AUTOSAR XML (schema 00052)
standard types defined: boolean, float32, uint16, uint8, boolean_CompuMethod
package /AUTOSAR_Platform/ImplementationDataTypes
  impl type uint8_const: category=VALUE, base-type=uint8, additional-native-type-qualifier=const  # uint8 represents integers with a minimum value of 0 and a maximum value of 255. The order-relation on uint8 is: x < y if y - x is positive. uint8 has a lexical representation consisting of a finite-length sequence of decimal digits (#x30-#x39). For example: 1, 0, 126, +10.
  impl type uint16_const: category=VALUE, base-type=uint16, additional-native-type-qualifier=const  # uint16 represents integers with a minimum value of 0 and a maximum value of 65535. The order-relation on uint16 is: x < y if y - x is positive. uint16 has a lexical representation consisting of a finite-length sequence of decimal digits (#x30-#x39). For example: 1, 0, 1267, +10000.
  impl type float32_const: category=VALUE, base-type=float32, additional-native-type-qualifier=const  # float32 corresponds to the IEEE single-precision 32-bit floating point type [IEEE 754-1985]. The basic value space of float32 consists of the values m * 2^e, where m is an integer whose absolute value is less than 2^24, and e is an integer between -149 and 104, inclusive. In addition to the basic value space described above, the value space of float32 also contains the following special values: positive and negative zero, positive and negative infinity and not-a-number. The order-relation on float32 is: x < y if y - x is positive. Positive zero is greater than negative zero. Not-a-number equals itself and is greater than all float values including positive infinity. float32 values have a lexical representation consisting of a mantissa followed, optionally, by the character "E" or "e", followed by an exponent. The exponent must be an integer. The mantissa must be a decimal number. The representations for exponent and mantissa must follow the lexical rules for integer and decimal. If the "E" or "e" and the following exponent are omitted, an exponent value of 0 is assumed. The special values positive and negative zero, positive and negative infinity and not-a-number have lexical representations 0, -0, INF, -INF and NaN, respectively. For example, -1E4, 1267.43233E12, 12.78e-2, 12 and INF are all legal literals for float32.
package /AUTOSAR_Platform/ImplementationDataTypes/SwAddrMethods
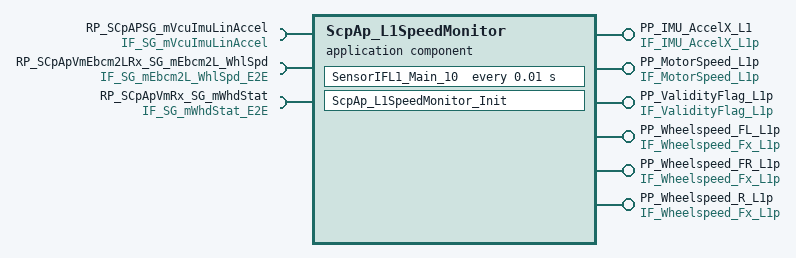
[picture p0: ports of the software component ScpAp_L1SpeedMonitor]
  application sw component type ScpAp_L1SpeedMonitor
    require port RP_SCpAPSG_mVcuImuLinAccel: nonqueued-receiver-com-spec{data-element=SG_mVcuImuLinAccel_VDP, init-value={short-label=DefaultInitValue_SG_mVcuImuLinAccel_IDT, fields=[0, 0, 0, 0, 0]}}, required-interface=IF_SG_mVcuImuLinAccel
    require port RP_SCpApVmEbcm2LRx_SG_mEbcm2L_WhlSpd: nonqueued-receiver-com-spec{data-element=SG_mEbcm2L_WhlSpd, init-value={short-label=ComSpec340e8554_2c4f562b67451db0, fields=[MsgCntr_mEbcm2L_WhlSpd:0, MsgCrc_mEbcm2L_WhlSpd:0, WhlSpdFL:0, WhlSpdFR:0, WhlSpdR:0, CanVm7FFltCod:0]}}, required-interface=IF_SG_mEbcm2L_WhlSpd_E2E
    require port RP_SCpApVmRx_SG_mWhdStat: nonqueued-receiver-com-spec{data-element=SG_mWhdStat, init-value={short-label=ComSpec652ee185_1335c2c789070b89, fields=[HwEnblStat:0, MsgCntr_mWhdStat:0, MsgCrc_mWhdStat:0, MtrSpd:0, MtrTrqEst:0, MvCurrEst:0, MvVolt:0, TrqEnblStat:0, CanVm64FltCod:0]}}, required-interface=IF_SG_mWhdStat_E2E
    6 x provide port:
      PP_IMU_AccelX_L1: nonqueued-sender-com-spec{data-element=IF_IMU_AccelX_L1p, init-value=ComSpec3740fc59_604787285220be46:0}, provided-interface=IF_IMU_AccelX_L1p
      PP_MotorSpeed_L1p: nonqueued-sender-com-spec{data-element=IF_MotorSpeed_L1p, init-value=ComSpec8213ca7e_f94256d2655c1c70:0}, provided-interface=IF_MotorSpeed_L1p
      PP_ValidityFlag_L1p: nonqueued-sender-com-spec{data-element=IF_ValidityFlag_L1p, init-value={short-label=ComSpec1d068168_c7023b00329d317b, fields=[Motor_RPM_Valid_Flg:0, WSS_FR_Valid_Flg:0, WSS_FL_Valid_Flg:0, WSS_R_Valid_Flg:0, IMU_AccelX_Valid_Flg:0, SensorStuck_Valid_Flg:0]}}, provided-interface=IF_ValidityFlag_L1p
      PP_Wheelspeed_FL_L1p: nonqueued-sender-com-spec{data-element=IF_Wheelspeed_Fx_L1p, init-value=0}, provided-interface=IF_Wheelspeed_Fx_L1p
      PP_Wheelspeed_FR_L1p: nonqueued-sender-com-spec{data-element=IF_Wheelspeed_Fx_L1p, init-value=0}, provided-interface=IF_Wheelspeed_Fx_L1p
      PP_Wheelspeed_R_L1p: nonqueued-sender-com-spec{data-element=IF_Wheelspeed_Fx_L1p, init-value=0}, provided-interface=IF_Wheelspeed_Fx_L1p
    behavior ScpAp_L1SpeedMonitor_InternalBehavior: handle-termination-and-restart=NO-SUPPORT
      constant-memorys:
        8 x parameter data prototype, all with category=VALUE, sw-addr-method=CALIB, sw-calibration-access=READ-WRITE:
          Accel_Max: type=float64_const, init-value=Accel_Max:32.767
          Alpha_Accel_IMU: type=float64_const, init-value=Alpha_Accel_IMU:0.15
          Alpha_Motor: type=float64_const, init-value=Alpha_Motor:0.45
          Alpha_WSS: type=float64_const, init-value=Alpha_WSS:0.35
          Motor_Spd_Max: type=uint16_const, init-value=Motor_Spd_Max:1023
          Motor_Spd_Min: type=uint16_const, init-value=Motor_Spd_Min:0
          WhlSpd_Max: type=uint16_const
          WhlSpd_Min: type=uint16_const
      static-memorys:
        45 x data, all with category=VALUE, sw-addr-method=AswVariable, sw-calibration-access=READ-ONLY:
          StuckCntOutput_Prev: type=float64
          IMU_AccelX_L1p_Prev: type=float32
          STC_IMU_Accel_XL1p_Prev: type=float32
          WSS_R_L1p_Prev: type=uint16
          WSS_FR_L1p_Prev: type=uint16
          WSS_FL_L1p_Prev: type=uint16
          STC_WSS_FR_L1p_Prev: type=uint16
          STC_WSS_FL_L1p_Prev: type=uint16
          STC_WSS_R_L1p_Prev: type=uint16
          MotorSpd_Equiv_L1p_Prev: type=uint8
          STC_MotorSpd_Equiv_L1p_Prev: type=uint8
          ScpAp_L1Spee_Cal_IMU_AccelX_L1p: type=float64
          ScpAp_L1SpeedMonitor_Output: type=float64
          ScpAp_L1SpeedMon_X_Accel_L1_Phy: type=float32
          ScpAp_L1SpeedMon_IMU_AccelX_L1p: type=float32
          ScpAp_L1SpeedMo_IMU_AccelX_Diff: type=float32
          ScpAp_L1SpeedM_WhlSpdFR_Phy_Kph: type=uint16
          ScpAp_L1SpeedMonitor_WSS_R_L1p: type=uint16
          ScpAp_L1SpeedMoni_Cal_WSS_R_L1p: type=uint16
          ScpAp_L1Spee_WhlSpdFR_Phy_Kph_n: type=uint16
          ScpAp_L1SpeedMonitor_WSS_FR_L1p: type=uint16
          ScpAp_L1SpeedMon_Cal_WSS_FR_L1p: type=uint16
          ScpAp_L1Spe_WhlSpdFR_Phy_Kph_nw: type=uint16
          ScpAp_L1SpeedMonitor_WSS_FL_L1p: type=uint16
          ScpAp_L1SpeedMon_Cal_WSS_FL_L1p: type=uint16
          ScpAp_L1SpeedMonito_WSS_FR_Diff: type=uint16
          ScpAp_L1SpeedMonito_WSS_FL_Diff: type=uint16
          ScpAp_L1SpeedMonitor_WSS_R_Diff: type=uint16
          ScpAp_L1Spee_MotorSpd_Equiv_L1p: type=uint8
          ScpAp_L1SpeedMonit_MotorSpd_kph: type=uint8
          ScpAp_L1_Cal_MotorSpd_Equiv_L1p: type=uint8
          ScpAp_L1Spe_MotorSpd_Equiv_Diff: type=uint8
          ScpAp_L1Speed_WhlSpdR_Valid_Chk: type=boolean
          ScpAp_L1SpeedMo_WSS_R_Valid_Flg: type=boolean
          ScpAp_L1Spee_WhlSpdFR_Valid_Chk: type=boolean
          ScpAp_L1SpeedM_WSS_FR_Valid_Flg: type=boolean
          ScpAp_L1Spee_WhlSpdFL_Valid_Chk: type=boolean
          ScpAp_L1SpeedM_WSS_FL_Valid_Flg: type=boolean
          ScpAp_L1Sp_Motor_Spd_ValidCheck: type=boolean
          ScpAp_L1Spe_Motor_RPM_Valid_Flg: type=boolean
          ScpAp_L1SpeedMo_IMU_Accel_Valid: type=boolean
          ScpAp_L1Sp_IMU_AccelX_Valid_Flg: type=boolean
          ScpAp_L1SpeedMoni_Chk_Stuck_Cnt: type=boolean
          ScpAp_L1SpeedMoni_Trg_Stuck_Cnt: type=boolean
          ScpAp_L1S_SensorStuck_Valid_Flg: type=boolean
      timing event TMT_SensorIF_L1_Main: start-on-event=SensorIFL1_Main_10, period=0.01
      runnable SensorIFL1_Main_10: sw-addr-method=CODE
        data-receive-point-by-arguments:
          access IN_RP_SCpAPSG_mVcuImuLinAccel_SG_mVcuImuLinAccel_VDP: accessed-variable=RP_SCpAPSG_mVcuImuLinAccel.SG_mVcuImuLinAccel_VDP
          access IN_RP_SCpApVmEbcm2LRx_SG_mEbcm2L_WhlSpd_SG_mEbcm2L_WhlSpd: accessed-variable=RP_SCpApVmEbcm2LRx_SG_mEbcm2L_WhlSpd.SG_mEbcm2L_WhlSpd
          access IN_RP_SCpApVmRx_SG_mWhdStat_SG_mWhdStat: accessed-variable=RP_SCpApVmRx_SG_mWhdStat.SG_mWhdStat
        data-send-points:
          6 x access:
            OUT_PP_IMU_AccelX_L1_IF_IMU_AccelX_L1p: accessed-variable=PP_IMU_AccelX_L1.IF_IMU_AccelX_L1p
            OUT_PP_MotorSpeed_L1p_IF_MotorSpeed_L1p: accessed-variable=PP_MotorSpeed_L1p.IF_MotorSpeed_L1p
            OUT_PP_ValidityFlag_L1p_IF_ValidityFlag_L1p: accessed-variable=PP_ValidityFlag_L1p.IF_ValidityFlag_L1p
            OUT_PP_Wheelspeed_FL_L1p_IF_Wheelspeed_Fx_L1p: accessed-variable=PP_Wheelspeed_FL_L1p.IF_Wheelspeed_Fx_L1p
            OUT_PP_Wheelspeed_FR_L1p_IF_Wheelspeed_Fx_L1p: accessed-variable=PP_Wheelspeed_FR_L1p.IF_Wheelspeed_Fx_L1p
            OUT_PP_Wheelspeed_R_L1p_IF_Wheelspeed_Fx_L1p: accessed-variable=PP_Wheelspeed_R_L1p.IF_Wheelspeed_Fx_L1p
      runnable ScpAp_L1SpeedMonitor_Init: sw-addr-method=CODE
package /DataTypes
  4 x impl type, all with category=STRUCTURE:
    IF_ValidityFlag_L1p_IDT
      6 x element, all with category=TYPE_REFERENCE, implementation-data-type=boolean:
        Motor_RPM_Valid_Flg
        WSS_FR_Valid_Flg
        WSS_FL_Valid_Flg
        WSS_R_Valid_Flg
        IMU_AccelX_Valid_Flg
        SensorStuck_Valid_Flg
    SG_mEbcm2L_WhlSpd_IDT_E2E
      6 x element, all with category=TYPE_REFERENCE:
        MsgCntr_mEbcm2L_WhlSpd: implementation-data-type=uint8
        MsgCrc_mEbcm2L_WhlSpd: implementation-data-type=uint8
        WhlSpdFL: implementation-data-type=float32
        WhlSpdFR: implementation-data-type=float32
        WhlSpdR: implementation-data-type=float32
        CanVm7FFltCod: implementation-data-type=uint8
    SG_mVcuImuLinAccel_IDT
      5 x element, all with category=TYPE_REFERENCE:
        MsgCntr_ImuLin: implementation-data-type=uint8
        MsgCrc_ImuLin: implementation-data-type=uint8
        X_Accel: implementation-data-type=float32
        Y_Accel: implementation-data-type=float32
        Z_Accel: implementation-data-type=float32
    SG_mWhdStat_IDT_E2E
      9 x element, all with category=TYPE_REFERENCE:
        HwEnblStat: implementation-data-type=boolean
        MsgCntr_mWhdStat: implementation-data-type=uint8
        MsgCrc_mWhdStat: implementation-data-type=uint8
        MtrSpd: implementation-data-type=float32
        MtrTrqEst: implementation-data-type=float32
        MvCurrEst: implementation-data-type=float32
        MvVolt: implementation-data-type=float32
        TrqEnblStat: implementation-data-type=boolean
        CanVm64FltCod: implementation-data-type=uint8
package /PortInterfaces
  7 x sender receiver interface:
    IF_IMU_AccelX_L1p: invalidation-policy{data-element=IF_IMU_AccelX_L1p, handle-invalid=DONT-INVALIDATE}
      data IF_IMU_AccelX_L1p: category=VALUE, sw-calibration-access=READ-ONLY, type=float32
    IF_MotorSpeed_L1p: invalidation-policy{data-element=IF_MotorSpeed_L1p, handle-invalid=DONT-INVALIDATE}
      data IF_MotorSpeed_L1p: category=VALUE, sw-calibration-access=READ-ONLY, type=uint8
    IF_SG_mEbcm2L_WhlSpd_E2E: invalidation-policy{data-element=SG_mEbcm2L_WhlSpd, handle-invalid=DONT-INVALIDATE}
      data SG_mEbcm2L_WhlSpd: category=STRUCTURE, sw-calibration-access=READ-ONLY, type=SG_mEbcm2L_WhlSpd_IDT_E2E
    IF_SG_mVcuImuLinAccel: invalidation-policy{data-element=SG_mVcuImuLinAccel_VDP, handle-invalid=DONT-INVALIDATE}
      data SG_mVcuImuLinAccel_VDP: category=STRUCTURE, sw-calibration-access=READ-ONLY, type=SG_mVcuImuLinAccel_IDT
    IF_SG_mWhdStat_E2E: invalidation-policy{data-element=SG_mWhdStat, handle-invalid=DONT-INVALIDATE}
      data SG_mWhdStat: category=STRUCTURE, sw-calibration-access=READ-ONLY, type=SG_mWhdStat_IDT_E2E
    IF_ValidityFlag_L1p: invalidation-policy{data-element=IF_ValidityFlag_L1p, handle-invalid=DONT-INVALIDATE}
      data IF_ValidityFlag_L1p: category=STRUCTURE, sw-calibration-access=READ-ONLY, type=IF_ValidityFlag_L1p_IDT
    IF_Wheelspeed_Fx_L1p: invalidation-policy{data-element=IF_Wheelspeed_Fx_L1p, handle-invalid=DONT-INVALIDATE}
      data IF_Wheelspeed_Fx_L1p: category=VALUE, sw-calibration-access=READ-ONLY, type=uint16
